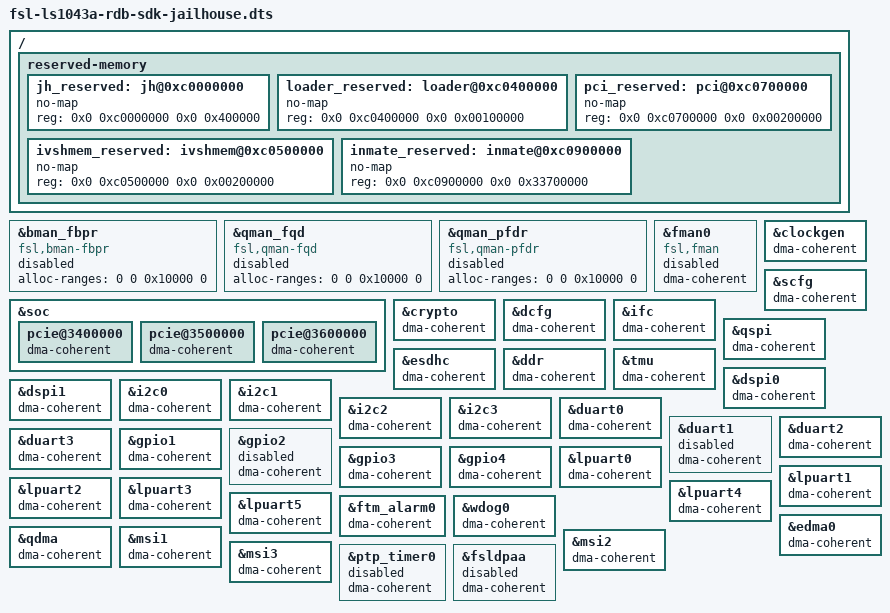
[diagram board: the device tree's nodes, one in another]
 // SPDX-License-Identifier: GPL-2.0+
/*
 * DTS file for NXP Layerscape-1043ARDB jailhouse case
 *
 * Copyright 2018-2023 NXP
 *
 * Author: Hongbo Wang <hongbo.wang@nxp.com>
 *
 */

#include "fsl-ls1043a-rdb.dts"
#include "qoriq-qman-portals-sdk.dtsi"
#include "qoriq-bman-portals-sdk.dtsi"

/ {
       reserved-memory {
               #address-cells = <2>;
               #size-cells = <2>;
               ranges;

                /* Reserve 832MB for Jailhouse from 0xc000,0000 */
                /* 4MB */
                jh_reserved: jh@0xc0000000 {
                        no-map;
                        reg = <0x0 0xc0000000 0x0 0x400000>;
                };
                /* 1MB */
                loader_reserved: loader@0xc0400000 {
                        no-map;
                        reg = <0x0 0xc0400000 0x0 0x00100000>;
                };
                /* 2MB */
                ivshmem_reserved: ivshmem@0xc0500000 {
                        no-map;
                        reg = <0x0 0xc0500000 0x0 0x00200000>;
                };
                /* 2MB */
                pci_reserved: pci@0xc0700000 {
                        no-map;
                        reg = <0x0 0xc0700000 0x0 0x00200000>;
                };
                /* 823MB */
                inmate_reserved: inmate@0xc0900000 {
                        no-map;
                        reg = <0x0 0xc0900000 0x0 0x33700000>;
                };
       };
};

&bman_fbpr {
	compatible = "fsl,bman-fbpr";
	alloc-ranges = <0 0 0x10000 0>;
};
&qman_fqd {
	compatible = "fsl,qman-fqd";
	alloc-ranges = <0 0 0x10000 0>;
};
&qman_pfdr {
	compatible = "fsl,qman-pfdr";
	alloc-ranges = <0 0 0x10000 0>;
};

&soc {
/delete-property/ dma-coherent;

#include "qoriq-dpaa-eth.dtsi"
#include "qoriq-fman3-0-6oh.dtsi"

pcie@3400000 {
	/delete-property/ iommu-map;
	dma-coherent;
};

pcie@3500000 {
	/delete-property/ iommu-map;
	dma-coherent;
};

pcie@3600000 {
	/delete-property/ iommu-map;
	dma-coherent;
};

/delete-node/ iommu@9000000;
/delete-node/ qman@1880000;
/delete-node/ bman@1890000;
/delete-node/ bman-portals@508000000;
/delete-node/ qman-portals@500000000;
};

&fman0 {
	compatible = "fsl,fman", "simple-bus";
};

&clockgen {
	dma-coherent;
};

&scfg {
	dma-coherent;
};

&crypto {
	dma-coherent;
};

&dcfg {
	dma-coherent;
};

&ifc {
	dma-coherent;
};

&qspi {
	dma-coherent;
};

&esdhc {
	dma-coherent;
};

&ddr {
	dma-coherent;
};

&tmu {
	dma-coherent;
};

&dspi0 {
	dma-coherent;
};

&dspi1 {
	dma-coherent;
};

&i2c0 {
	dma-coherent;
};

&i2c1 {
	dma-coherent;
};

&i2c2 {
	dma-coherent;
};

&i2c3 {
	dma-coherent;
};

&duart0 {
	dma-coherent;
	/delete-property/ interrupts;
};

&duart1 {
	dma-coherent;
	status = "disabled";
};

&duart2 {
	dma-coherent;
};

&duart3 {
	dma-coherent;
};

&gpio1 {
	dma-coherent;
};

&gpio2 {
	dma-coherent;
	status = "disabled";
};

&gpio3 {
	dma-coherent;
};

&gpio4 {
	dma-coherent;
};

&lpuart0 {
	dma-coherent;
};

&lpuart1 {
	dma-coherent;
};

&lpuart2 {
	dma-coherent;
};

&lpuart3 {
	dma-coherent;
};

&lpuart4 {
	dma-coherent;
};

&lpuart5 {
	dma-coherent;
};

&ftm_alarm0 {
	dma-coherent;
};

&wdog0 {
	dma-coherent;
};

&edma0 {
	dma-coherent;
};

&qdma {
	dma-coherent;
};

&msi1 {
	dma-coherent;
};

&msi2 {
	dma-coherent;
};

&msi3 {
	dma-coherent;
};

&fman0 {
	dma-coherent;
	status = "disabled";
};

&ptp_timer0 {
	dma-coherent;
	status = "disabled";
};

&fsldpaa {
	dma-coherent;
	status = "disabled";
};

&bman_fbpr {
	status = "disabled";
};

&qman_fqd {
	status = "disabled";
};

&qman_pfdr {
	status = "disabled";
};
